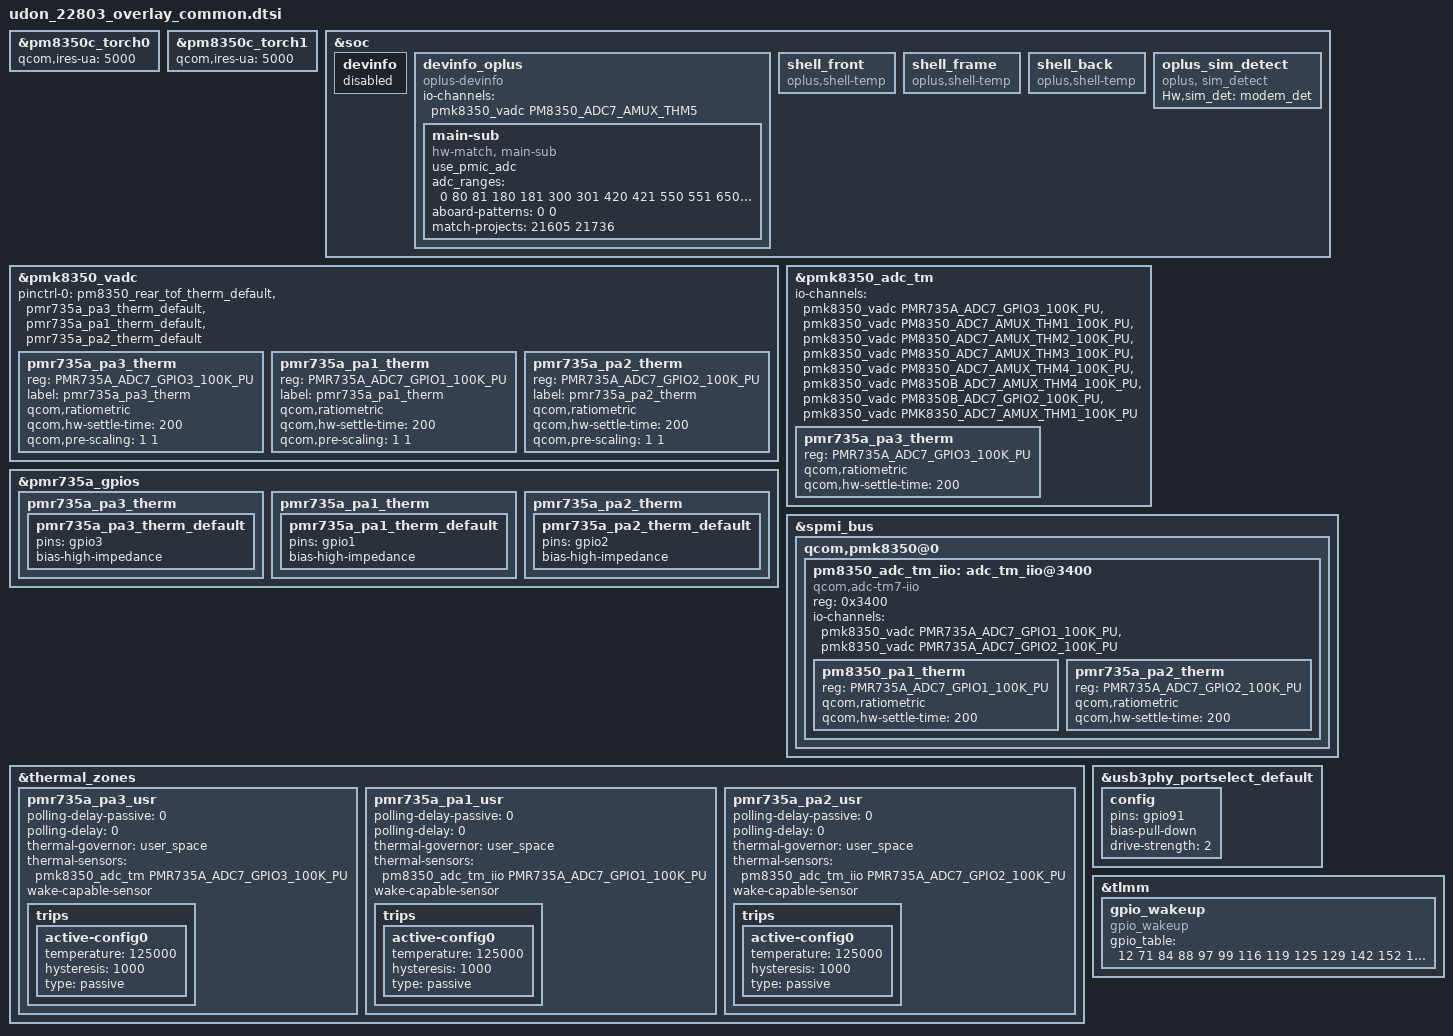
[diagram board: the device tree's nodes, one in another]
/* Cape configurations for PM8010I and PM8010J connected via SPMI */

#include <dt-bindings/regulator/qcom,rpmh-regulator-levels.h>

&pm8350c_torch0 {
	qcom,ires-ua = <5000>;
};

&pm8350c_torch1 {
	qcom,ires-ua = <5000>;
};
&soc {
    devinfo {
        status = "disabled";
    };

	devinfo_oplus {
		compatible = "oplus-devinfo";

		//pinctrl-names = "active", "sleep";
		//pinctrl-0 = <&hw_id_active>;
		//pinctrl-1 = <&hw_id_sleep>;

		io-channels= <&pmk8350_vadc PM8350_ADC7_AMUX_THM5>;
		io-channel-names= "vph_pwr_voltage_sub";

		main-sub {
			compatible = "hw-match, main-sub";
			use_pmic_adc;
			adc_ranges = <0 80
					81 180
					181 300
					301 420
					421 550
					551 650
					651 760
					761 850
					851 950
					951 1050
					1051 1150
					1151 1300>;
			aboard-patterns = <0 0>;

			/*main board*/
			match-projects = <21605 21736>;
		};
	};
	//#ifdef OPLUS_FEATURE_THERMAL_HORAE
	shell_front {
			compatible = "oplus,shell-temp";
	};

	shell_frame {
			compatible = "oplus,shell-temp";
	};

	shell_back {
			compatible = "oplus,shell-temp";
	};
	//#endif

	//#ifdef OPLUS_FEATRUE_DUAL_SIM_DETECT
	oplus_sim_detect {
		compatible = "oplus, sim_detect";
		Hw,sim_det = "modem_det";
	};
    //#endif /* OPLUS_FEATRUE_DUAL_SIM_DETECT */
};

&pmk8350_vadc {
	pinctrl-names = "default";
	pinctrl-0 = <&pm8350_rear_tof_therm_default &pmr735a_pa3_therm_default &pmr735a_pa1_therm_default &pmr735a_pa2_therm_default>;

	/delete-node/ pm8350_rear_tof_therm;

	pmr735a_pa3_therm {
		reg = <PMR735A_ADC7_GPIO3_100K_PU>;
		label = "pmr735a_pa3_therm";
		qcom,ratiometric;
		qcom,hw-settle-time = <200>;
		qcom,pre-scaling = <1 1>;
	};

	pmr735a_pa1_therm {
		reg = <PMR735A_ADC7_GPIO1_100K_PU>;
		label = "pmr735a_pa1_therm";
		qcom,ratiometric;
		qcom,hw-settle-time = <200>;
		qcom,pre-scaling = <1 1>;
	};

	pmr735a_pa2_therm {
		reg = <PMR735A_ADC7_GPIO2_100K_PU>;
		label = "pmr735a_pa2_therm";
		qcom,ratiometric;
		qcom,hw-settle-time = <200>;
		qcom,pre-scaling = <1 1>;
	};
};

&pmr735a_gpios {
	pmr735a_pa3_therm {
         pmr735a_pa3_therm_default: pmr735a_pa3_therm_default {
               pins = "gpio3";
               bias-high-impedance;
         };
      };

	pmr735a_pa1_therm {
		pmr735a_pa1_therm_default: pmr735a_pa1_therm_default {
			pins = "gpio1";
			bias-high-impedance;
		};
	};

	pmr735a_pa2_therm {
         pmr735a_pa2_therm_default: pmr735a_pa2_therm_default {
               pins = "gpio2";
               bias-high-impedance;
         };
      };
};

&pmk8350_adc_tm {
	io-channels = <&pmk8350_vadc PMR735A_ADC7_GPIO3_100K_PU>,
			<&pmk8350_vadc PM8350_ADC7_AMUX_THM1_100K_PU>,
			<&pmk8350_vadc PM8350_ADC7_AMUX_THM2_100K_PU>,
			<&pmk8350_vadc PM8350_ADC7_AMUX_THM3_100K_PU>,
			<&pmk8350_vadc PM8350_ADC7_AMUX_THM4_100K_PU>,
			<&pmk8350_vadc PM8350B_ADC7_AMUX_THM4_100K_PU>,
			<&pmk8350_vadc PM8350B_ADC7_GPIO2_100K_PU>,
			<&pmk8350_vadc PMK8350_ADC7_AMUX_THM1_100K_PU>;

	/delete-node/ pm8350_rear_tof_therm;

	pmr735a_pa3_therm {
		reg = <PMR735A_ADC7_GPIO3_100K_PU>;
		qcom,ratiometric;
		qcom,hw-settle-time = <200>;
	};
};

&spmi_bus {
	qcom,pmk8350@0 {
		pm8350_adc_tm_iio: adc_tm_iio@3400 {
			/* Alternate ADC_TM DT node */
			compatible = "qcom,adc-tm7-iio";
			/* With this entry, a feature-reduced
			version of the driver is initialized (only
			thermistor reads, no interrupt functionality
			for exposed thermistors) */
			reg = <0x3400>;
			#thermal-sensor-cells = <1>;
			#address-cells = <1>;
			#size-cells = <0>;
			io-channels = <&pmk8350_vadc PMR735A_ADC7_GPIO1_100K_PU>,
						<&pmk8350_vadc PMR735A_ADC7_GPIO2_100K_PU>;
			/* Similar to io-channels in actual ADC_TM node,
			for reading thermistor temperature from
			VADC */

			pm8350_pa1_therm {
				reg = <PMR735A_ADC7_GPIO1_100K_PU>;
				qcom,ratiometric;
				qcom,hw-settle-time = <200>;
			};

			pmr735a_pa2_therm {
				reg = <PMR735A_ADC7_GPIO2_100K_PU>;
				qcom,ratiometric;
				qcom,hw-settle-time = <200>;
			};

		};
	};
};

&thermal_zones {

	/delete-node/ pm8350_rear_tof_therm;

	pmr735a_pa3_usr {
		polling-delay-passive = <0>;
		polling-delay = <0>;
		thermal-governor = "user_space";
		thermal-sensors = <&pmk8350_adc_tm PMR735A_ADC7_GPIO3_100K_PU>;
		wake-capable-sensor;
		trips {
			active-config0 {
				temperature = <125000>;
				hysteresis = <1000>;
				type = "passive";
			};
		};
	};

	pmr735a_pa1_usr {
		polling-delay-passive = <0>;
		polling-delay = <0>;
		thermal-governor = "user_space";
		thermal-sensors = <&pm8350_adc_tm_iio PMR735A_ADC7_GPIO1_100K_PU>;
		wake-capable-sensor;
		trips {
			active-config0 {
				temperature = <125000>;
				hysteresis = <1000>;
				type = "passive";
			};
		};
	};

	pmr735a_pa2_usr {
		polling-delay-passive = <0>;
		polling-delay = <0>;
		thermal-governor = "user_space";
		thermal-sensors = <&pm8350_adc_tm_iio PMR735A_ADC7_GPIO2_100K_PU>;
		wake-capable-sensor;
		trips {
			active-config0 {
				temperature = <125000>;
				hysteresis = <1000>;
				type = "passive";
			};
		};
	};

};
/*
&xo_config2 {
	temperature = <125000>;
	hysteresis = <10000>;
	type = "passive";
};
*/
&usb3phy_portselect_default {
	config {
		pins = "gpio91";
		bias-pull-down;
		drive-strength = <2>;
	};
};

&tlmm {
	gpio_wakeup: gpio_wakeup {
		compatible = "gpio_wakeup";
		gpio_table = <12 71 84 88 97 99  116 119 125 129 142 152 154 174 177 180 181 186 187>;
	};
};
